# AST2600 register map
File version: 1.1
CPU: CM3 r1p0, little endian, no MPU, no FPU, 3 interrupt priority bits
Registers are 32-bit, read-write, reset 0x0 unless marked. A register's access mark holds for its fields unless they carry their own. Offsets are from the block's base; lines under a group give offsets from that group; [hi:lo] are bit positions; {n}, {i} and the like mark numbered series; 'fields as' and 'values as' point back to an identical list; <NAME> marks a mode.

## Memory map
0xE000E010 SYSTICK size 0x10 — SysTick Timer
0xE000E100 NVIC size 0x4F0 — Nested Vectored Interrupt Controller
0xE000ED00 SCB size 0x90 — System Control Block
0xE000EDF0 DCB size 0x10 — Debug Control Block
0xE000EF00 SIG size 0x4 — Software Interrupt Generation

## SIG — Software Interrupt Generation
Base 0xE000EF00
0x00 Software Triggered Interrupt Register wo — Provides a mechanism for software to generate an interrupt
  [8:0] INTID — Indicates the interrupt to be triggered

## SYSTICK — SysTick Timer
Base 0xE000E010
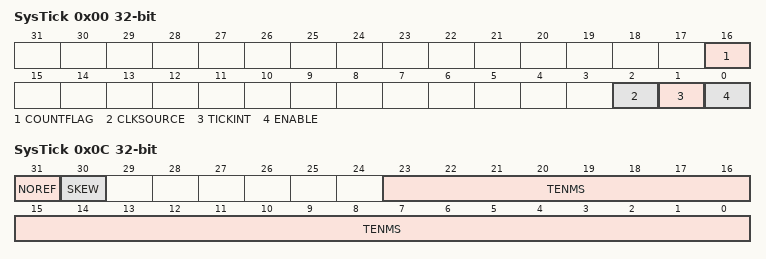
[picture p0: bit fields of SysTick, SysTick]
0x00 SysTick Control and Status Register — Controls the system timer and provides status data
  [16] COUNTFLAG — Indicates whether the counter has counted to 0 since the last read of this register
    0=Timer has not counted to 0; 1=Timer has counted to 0
  [2] CLKSOURCE — Indicates the SysTick clock source
    0=SysTick uses the IMPLEMENTATION DEFINED external reference clock; 1=SysTick uses the processor clock
  [1] TICKINT — Indicates whether counting to 0 causes the status of the SysTick exception to change to pending
    0=Count to 0 does not affect the SysTick exception status; 1=Count to 0 changes the SysTick exception status to pending
  [0] ENABLE — Indicates the enabled status of the SysTick counter
    0=Counter is disabled; 1=Counter is operating
0x04 SysTick Reload Value Register — Holds the reload value of the SYST_CVR
  [23:0] RELOAD — The value to load into the SYST_CVR when the counter reaches 0
0x08 SysTick Current Value Register — Reads or clears the current counter value
  [31:0] CURRENT — Current counter value
0x0C SysTick Calibration value Register ro — Reads the calibration value and parameters for SysTick
  [31] NOREF — Indicates whether the IMPLEMENTATION DEFINED reference clock is implemented
    0=The reference clock is implemented; 1=The reference clock is not implemented
  [30] SKEW — Indicates whether the 10ms calibration value is exact
    0=10ms calibration value is exact; 1=10ms calibration value is inexact, because of the clock frequency
  [23:0] TENMS — Optionally, holds a reload value to be used for 10ms (100Hz) timing, subject to system clock skew errors

## NVIC — Nested Vectored Interrupt Controller
Base 0xE000E100
{0x0+4i} Interrupt Set-Enable Register {i} (i=0..7) — Enables, or reads the enable state of a group of interrupts
{0x80+4i} Interrupt Clear-Enable Register {i} (i=0..7) — Disables, or reads the enable state of, a group of registers
{0x100+4i} Interrupt Set-Pending Register {i} (i=0..7) — For a group of interrupts, changes interrupt status to pending, or shows the current pending status
{0x180+4i} Interrupt Clear-Pending Register {i} (i=0..7) — For a group of interrupts, clears the interrupt pending status, or shows the current pending status
{0x200+4i} Interrupt Active Bit Register {i} (i=0..7) ro — For a group of 32 interrupts, shows whether each interrupt is active
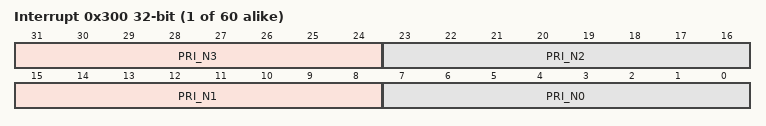
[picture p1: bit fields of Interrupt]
{0x300+4i} Interrupt Priority Register {i} (i=0..59) — Sets or reads interrupt priorities
  [31:24] PRI_N3 — For register NVIC_IPRn, priority of interrupt number 4n+3
  [23:16] PRI_N2 — For register NVIC_IPRn, priority of interrupt number 4n+2
  [15:8] PRI_N1 — For register NVIC_IPRn, priority of interrupt number 4n+1
  [7:0] PRI_N0 — For register NVIC_IPRn, priority of interrupt number 4n
